AUTOSAR XML (schema 00044)
package /E40_Platform_System_SystemPackage/Components
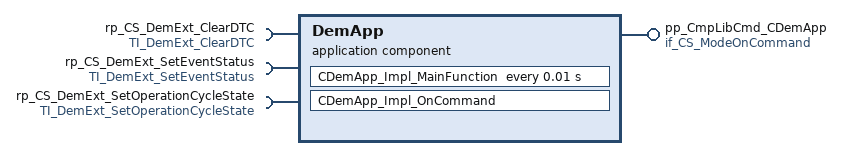
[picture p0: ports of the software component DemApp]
  application sw component type DemApp
    provide port pp_CmpLibCmd_CDemApp: server-com-spec{operation=Impl_OnCommand, queue-length=1}, provided-interface=if_CS_ModeOnCommand
    require port rp_CS_DemExt_ClearDTC: client-com-spec=DemExt_ClearDTC, required-interface=TI_DemExt_ClearDTC
    require port rp_CS_DemExt_SetEventStatus: client-com-spec=DemExt_SetEventStatus, required-interface=TI_DemExt_SetEventStatus
    require port rp_CS_DemExt_SetOperationCycleState: client-com-spec=DemExt_SetOperationCycleState, required-interface=TI_DemExt_SetOperationCycleState
    behavior IB_DemApp
      timing event TECDemApp_Impl_MainFunction: start-on-event=CDemApp_Impl_MainFunction, period=0.01
      operation invoked event OIE_pp_CmpLibCmd_CDemApp_CDemApp_Impl_OnCommandTrigByImpl_OnCommand: start-on-event=CDemApp_Impl_OnCommand, operation=pp_CmpLibCmd_CDemApp.Impl_OnCommand
      port-api-options:
        enable-take-address=false, indirect-api=false, port=pp_CmpLibCmd_CDemApp
        enable-take-address=false, indirect-api=false, port=rp_CS_DemExt_ClearDTC
        enable-take-address=false, indirect-api=false, port=rp_CS_DemExt_SetEventStatus
        enable-take-address=false, indirect-api=false, port=rp_CS_DemExt_SetOperationCycleState
      runnable CDemApp_Impl_MainFunction: can-be-invoked-concurrently=true
        sync call OA_rp_CS_DemExt_ClearDTC_DemExt_ClearDTC: operation=rp_CS_DemExt_ClearDTC.DemExt_ClearDTC
        sync call OA_rp_CS_DemExt_SetEventStatus_DemExt_SetEventStatus: operation=rp_CS_DemExt_SetEventStatus.DemExt_SetEventStatus
        sync call OA_rp_CS_DemExt_SetOperationCycleState_DemExt_SetOperationCycleState: operation=rp_CS_DemExt_SetOperationCycleState.DemExt_SetOperationCycleState
      runnable CDemApp_Impl_OnCommand: can-be-invoked-concurrently=true
        sync call OA_rp_CS_DemExt_ClearDTC_DemExt_ClearDTC: operation=rp_CS_DemExt_ClearDTC.DemExt_ClearDTC
        sync call OA_rp_CS_DemExt_SetEventStatus_DemExt_SetEventStatus: operation=rp_CS_DemExt_SetEventStatus.DemExt_SetEventStatus
        sync call OA_rp_CS_DemExt_SetOperationCycleState_DemExt_SetOperationCycleState: operation=rp_CS_DemExt_SetOperationCycleState.DemExt_SetOperationCycleState
  swc implementation IMPL_DemApp: behavior=IB_DemApp
